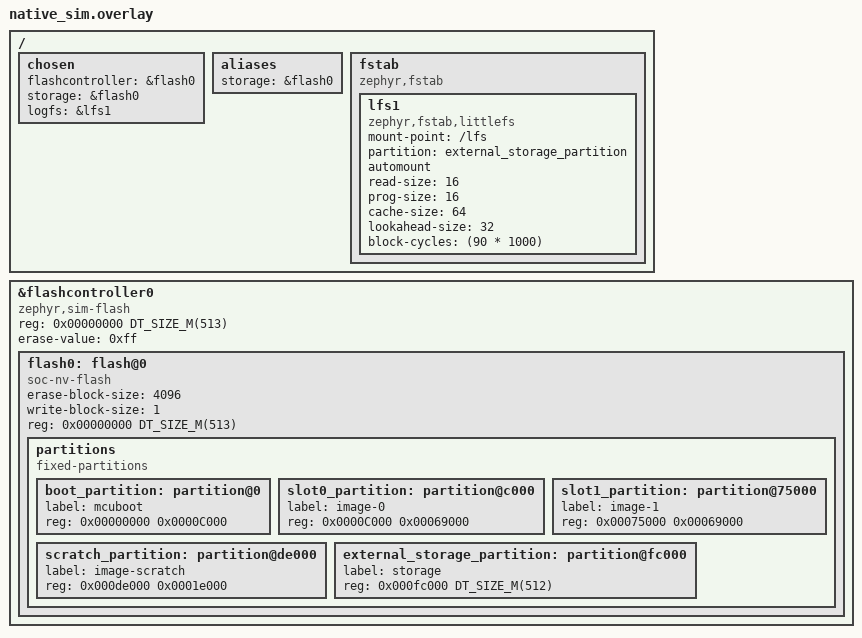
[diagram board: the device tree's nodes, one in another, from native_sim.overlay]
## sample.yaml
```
sample:
  description: datalogger
  name: datalogger
common:
  build_only: true
  platform_allow:
    - native_sim
tests:
  samples.datalogger.default: {}
```

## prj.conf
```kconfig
CONFIG_CPP=y
CONFIG_REQUIRES_FULL_LIBCPP=y
CONFIG_STD_CPP20=y

CONFIG_F_CORE=y
CONFIG_F_CORE_OS=y

 # outputs
CONFIG_SERIAL=y

CONFIG_SHELL=y
CONFIG_FILE_SYSTEM_SHELL=y
CONFIG_HEAP_MEM_POOL_SIZE=8192


CONFIG_DEBUG=y
CONFIG_LOG=y
CONFIG_LOG_MODE_IMMEDIATE=y
CONFIG_CBPRINTF_FP_SUPPORT=y


# Flash chip is SPI
CONFIG_FLASH=y
# LittleFS requires a flash map device
CONFIG_FLASH_MAP=y
CONFIG_FLASH_PAGE_LAYOUT=y

# Use filesystem
# LittleFS is mounted on a flash map device
CONFIG_FS_LITTLEFS_FMP_DEV=y 

# LittleFS's buffers get large
CONFIG_MAIN_STACK_SIZE=8192
```

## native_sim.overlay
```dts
/ {
	chosen {
		flashcontroller = &flash0;
		storage = &flash0;
		logfs = &lfs1;
	};

	aliases {
		storage = &flash0;
	};


	fstab {
		compatible = "zephyr,fstab";
		lfs1: lfs1 {
			compatible = "zephyr,fstab,littlefs";
			mount-point = "/lfs";
			partition = <&external_storage_partition>;
			automount;

			// the binding reccomends defaults for these
			read-size = <16>;
			prog-size = <16>;
			cache-size = <64>; // may need to grow for optimization
			lookahead-size = <32>;
			block-cycles = <(90 * 1000)>;
			// the datasheet gives 100K P-E cycles
			// NOTE: this seems to default to 512 for the mounted filesystem
			// anyway
		};
	};

};

&flashcontroller0 {
	status = "okay";
	compatible = "zephyr,sim-flash";
	reg = <0x00000000 DT_SIZE_M(513)>;

	#address-cells = <1>;
	#size-cells = <1>;
	erase-value = <0xff>;

	flash0: flash@0 {
		status = "okay";
		compatible = "soc-nv-flash";
		erase-block-size = <4096>;
		write-block-size = <1>;
		reg = <0x00000000 DT_SIZE_M(513)>; // builtin stuff + external flash simulation

		partitions {
			compatible = "fixed-partitions";
			#address-cells = <1>;
			#size-cells = <1>;

			boot_partition: partition@0 {
				label = "mcuboot";
				reg = <0x00000000 0x0000C000>;
			};
			slot0_partition: partition@c000 {
				label = "image-0";
				reg = <0x0000C000 0x00069000>;
			};
			slot1_partition: partition@75000 {
				label = "image-1";
				reg = <0x00075000 0x00069000>;
			};
			scratch_partition: partition@de000 {
				label = "image-scratch";
				reg = <0x000de000 0x0001e000>;
			};
			external_storage_partition: partition@fc000 {
				label = "storage";
				reg = <0x000fc000 DT_SIZE_M(512)>;
			};
		};
	};
};
```

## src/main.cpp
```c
#include "f_core/os/c_fs_datalogger.h"

#include <zephyr/kernel.h>

struct Packet {
    uint8_t a;
    uint8_t b;
};
CFsDataLogger<Packet> expand_logger{"/lfs/expand.bin"};
CFsDataLogger<Packet> fill_logger{"/lfs/fill.bin", LogMode::FixedSize, 10};
CFsDataLogger<Packet> wrap_logger{"/lfs/wrap.bin", LogMode::Circular, 10};

int main() {
    for (uint8_t i = 0; i < 100; i++) {
        expand_logger.Write({i, (uint8_t) (100 - i)});
        fill_logger.Write({i, (uint8_t) (100 - i)});
        wrap_logger.Write({i, (uint8_t) (100 - i)});
        k_msleep(10);
    }
    expand_logger.Close();
    fill_logger.Close();
    wrap_logger.Close();
    printk("Finished!\n");
    return 0;
}
```
